# SYNTH register map
File version: 1.0
hand-written probe of dim, clusters, derivedFrom and value formats
CPU: CM33 r0p1, MPU, FPU, 3 interrupt priority bits
Registers are 32-bit, access not given, no defined reset value unless marked. A register's access mark holds for its fields unless they carry their own. Offsets are from the block's base; lines under a group give offsets from that group; [hi:lo] are bit positions; {n}, {i} and the like mark numbered series; 'fields as' and 'values as' point back to an identical list; <NAME> marks a mode.

## Memory map
0x40000000 A size 0x400
0x40001000 B size 0x400
0x40002000 C size 0x400
0x40003000 D size 0x400
0x50003000 SEC_D size 0x400

## Interrupts
3 A_IRQ (A)

## A
Base 0x40000000
Same registers: B 0x40001000
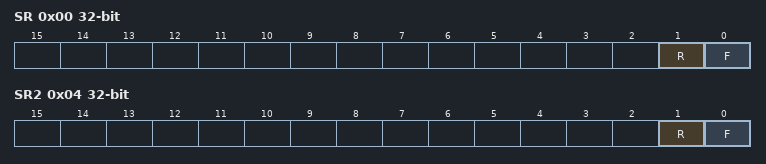
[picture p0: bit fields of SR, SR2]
0x00 SR
  [1] R read-clears, [0] F write-1-clears
0x04 SR2 — derived, with an empty alternateRegister meaning absent
  [1] R read-clears, [0] F write-1-clears
{0x10+4i} ARR{i} (i=0..3)
  [7:0] V
{0x100+0x20*i} CH{i} (i=0..1) group
  0x00 CR
    [0] EN
  0x10 SUB group
    0x00 DR

## C
Base 0x40002000
0x00 VIEW_A reset 0x0 (CTRL view)
0x00 VIEW_B reset 0x0 (CTRL view)

## D
Base 0x40003000
Same registers: SEC_D 0x50003000
0x00 CR reset 0x0
  [0] EN
